# SC32F12XRX48 register map
File version: 1.0
CPU: CM0+ r0p1, little endian, MPU, no FPU, 4 interrupt priority bits
Registers are 32-bit, read-write, reset 0x0 unless marked. A register's access mark holds for its fields unless they carry their own. Offsets are from the block's base; [hi:lo] are bit positions; {n}, {i} and the like mark numbered series.

## TIM0 — General purpose timers
Base 0x40020100
Same registers: TIM1 0x40020140, TIM2 0x40020180, TIM3 0x400201C0, TIM4 0x40021100, TIM5 0x40021140, TIM6 0x40021180, TIM7 0x400211C0
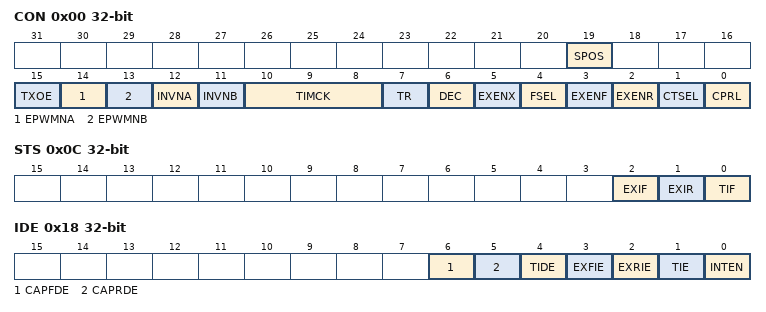
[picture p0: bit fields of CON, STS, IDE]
0x00 CON — control register
  [19] SPOS — Timer port control
  [15] TXOE — Timer external port control
  [14] EPWMNA — PWMA output waveform enable
  [13] EPWMNB — PWMB output waveform enable
  [12] INVNA — PWMA output waveform reverse
  [11] INVNB — PWMB output waveform reverse
  [10:8] TIMCK — Timer clock control
  [7] TR — Timer control
  [6] DEC — Decline increasing control
  [5] EXENX — External port capture enable
  [4] FSEL — Falling edge capture enable
  [3] EXENF — External port Enable falling
  [2] EXENR — External port Enable rising
  [1] CTSEL — Count/timer select
  [0] CPRL — Control Capture/reload enable
0x04 CNT — count register
  [15:0] CNT — Timer count
0x08 RLD — Reload register
  [15:0] RLD — Reload timer count
0x0C STS — status register
  [2] EXIF — Capture falling interrupt flag
  [1] EXIR — Capture rising interrupt flag
  [0] TIF — Capture/Compare 1 overcapture flag
0x10 PDTA_RCAP — Rising capture/Duty set register
  [15:0] PDTA_RCAP — Duty/Rising capture
0x14 PDTB_FCAP — Falling capture/Duty set register
  [15:0] PDTB_FCAP — Duty/Falling capture
0x18 IDE — interrut enable register
  [6] CAPFDE — Capture falling event trig DMA
  [5] CAPRDE — Capture rising event trig DMA
  [4] TIDE — Timer overflow event trig DMA
  [3] EXFIE — External falling event Capture
  [2] EXRIE — External rising event Capture
  [1] TIE — Timer overflow
  [0] INTEN — Interrupt request

## ADC — Analog to Digital Converter instance
Base 0x40022110
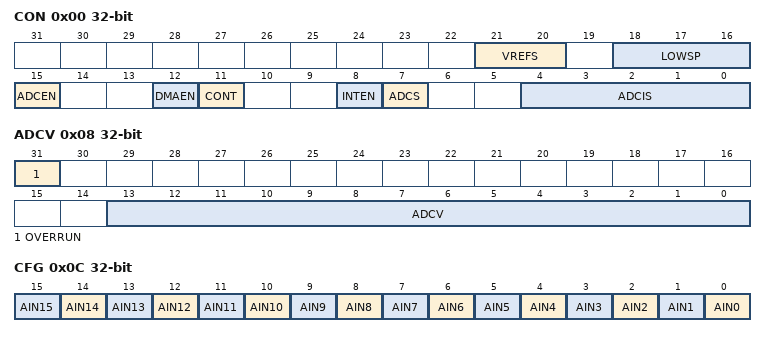
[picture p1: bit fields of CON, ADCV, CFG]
0x00 CON — ADC interrupt and status register
  [21:20] VREFS — ADC reference voltage selection flag
  [18:16] LOWSP — ADC sampling period selection flag
  [15] ADCEN — Start the power supply to the ADC
  [12] DMAEN — Direct memory access flag
  [11] CONT — Single/continuous conversion mode
  [8] INTEN — Interrupt flag of the request CPU
  [7] ADCS — The ADC starts to trigger the control
  [4:0] ADCIS — Channel choice flag
0x04 STS — ADC status bit register
  [0] ADCIF — ADC Interrupt Flag
0x08 ADCV — ADC Convert value register
  [31] OVERRUN ro — ADC overrun flag
  [13:0] ADCV — ADC Convert value
0x0C CFG — ADC channel configuration register
  [n] AIN{n} (n=0..15) — ADC channel {n}

## TWI0 — Inter-integrated circuit 0
Base 0x40020060
Same registers: TWI1 0x40021060
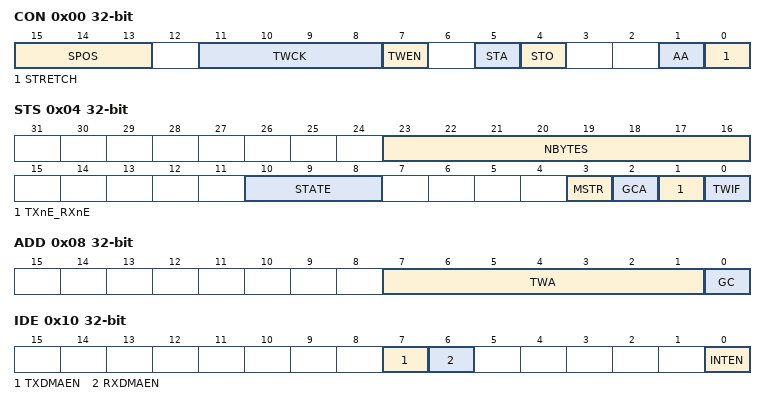
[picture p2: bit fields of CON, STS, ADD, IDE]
0x00 CON — Control register
  [15:13] SPOS — Select ports
  [11:8] TWCK — Master mode clock
  [7] TWEN — TWI enable
  [5] STA — Start byte
  [4] STO — Stop byte
  [1] AA — Answer enable
  [0] STRETCH — The clock to extend
0x04 STS — Stauts register
  [23:16] NBYTES — Number of bytes state
  [10:8] STATE — State machine state
  [3] MSTR — Master slaver mode
  [2] GCA — Universal address response flag
  [1] TXnE_RXnE — Send receive completion flag
  [0] TWIF — Interrput flag
0x08 ADD — address register
  [7:1] TWA — TWI address register
  [0] GC — General address
0x0C DATA
  [7:0] DATA
0x10 IDE — DMA control register
  [7] TXDMAEN — Transmit DMA enable
  [6] RXDMAEN — Receive DMA enable
  [0] INTEN — Interrupt enable

## PWM0 — Pulse Width Modulation 0 registers
Base 0x40020200
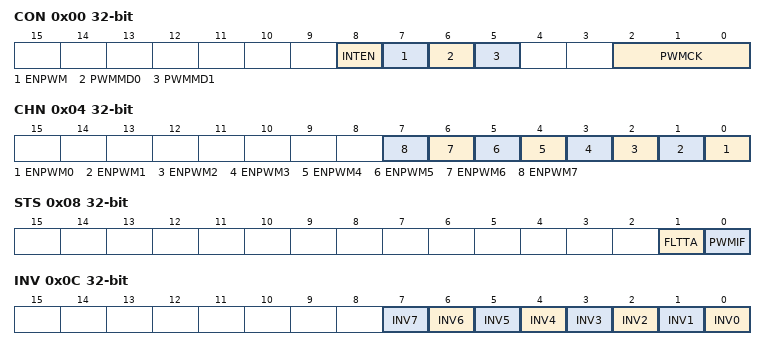
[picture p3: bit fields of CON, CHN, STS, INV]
0x00 CON — control register
  [8] INTEN — Interrupt enable
  [7] ENPWM — PWM enable
  [6] PWMMD0 — PWM mode 0
  [5] PWMMD1 — PWM mode 1
  [2:0] PWMCK
0x04 CHN — Channel register
  [n] ENPWM{n} (n=0..7) — PWM0 Channel{n} enable
0x08 STS — Status register
  [1] FLTTA — Fault flag
  [0] PWMIF — PWM interrupt flag
0x0C INV — Inverted Output register
  [n] INV{n} (n=0..7) — channel{n} inverted output
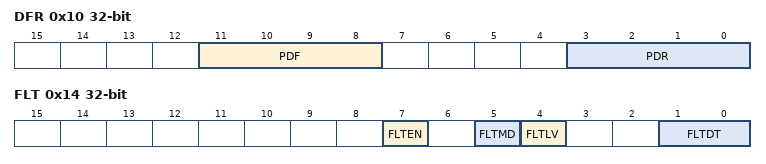
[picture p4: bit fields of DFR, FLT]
0x10 DFR — Dead zone fall rise register
  [11:8] PDF — Complementary modes fall along the dead zone
  [3:0] PDR — Complementary modes rise along the dead zone
0x14 FLT — Fault detect register
  [7] FLTEN — Fault enable
  [5] FLTMD — Fault mode
  [4] FLTLV — Fault detection level
  [1:0] FLTDT — Filtering input signal for PWM fault detection
0x18 CYCLE — PWM Cycle register
  [15:0] PWMPD
{0x30+4i} DT{i} (i=0..7) — Channel{i} duty cycle
  [15:0] PDT — PDT{i}

## LEDPWM — LED Pulse Width Modulation 1 registers
Base 0x40022300
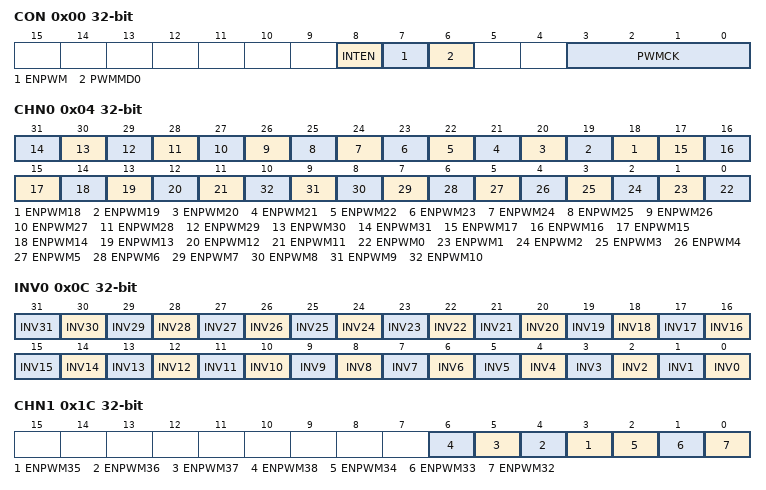
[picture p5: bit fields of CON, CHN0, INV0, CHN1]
0x00 CON — control register
  [8] INTEN — Interrupt enable
  [7] ENPWM — PWM enable
  [6] PWMMD0 — PWM mode 0
  [3:0] PWMCK
0x04 CHN0 — Channel0 register
  [n] ENPWM{n} (n=18..31) — PWM1 Channel{n} enable
  [17] ENPWM17 — PWM1 Channel7 enable
  [16] ENPWM16 — PWM1 Channel16 enable
  [15] ENPWM15 — PWM1 Channel15 enable
  [14] ENPWM14 — PWM1 Channel14 enable
  [13] ENPWM13 — PWM0 Channel13 enable
  [12] ENPWM12 — PWM1 Channel12 enable
  [11] ENPWM11 — PWM1 Channel11 enable
  [n] ENPWM{n} (n=0..10) — PWM0 Channel{n} enable
0x08 STS — Status register
  [0] PWMIF — PWM Interrupt flag
0x0C INV0 — Inverted Output register
  [n] INV{n} (n=0..31) — channel{n} inverted output
0x18 CYCLE — LEDPWM Cycle register
  [7:0] PWMPD
0x1C CHN1 — Channel1 register
  [n-32] ENPWM{n} (n=35..38) — PWM0 Channel{n} enable
  [2] ENPWM34 — LEDPWM Channel34 enable
  [1] ENPWM33 — LEDPWM Channel33 enable
  [0] ENPWM32 — LEDPWM Channe32 enable
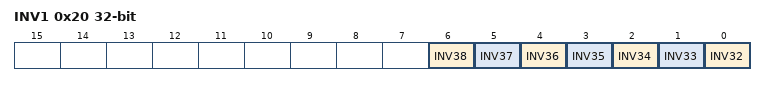
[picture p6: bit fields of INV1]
0x20 INV1 — Inverted Output register
  [n-32] INV{n} (n=32..38) — channel{n} inverted output
{0x30+4i} DT{i} (i=0..38) — Channel{i} duty cycle
  [7:0] PDT — PDT{i}
